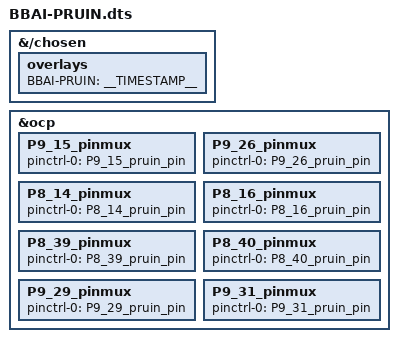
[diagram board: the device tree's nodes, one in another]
/*
 * Copyright (C) 2020 Deepak Khatri <deepaklorkhatri7@gmail.com>
 * See Cape Interface Spec page for more info on Bone Buses
 * https://elinux.org/Beagleboard:BeagleBone_cape_interface_spec
 *
 * Virtual cape for pr2_pru0_gpi* pins
 *
 * This program is free software; you can redistribute it and/or modify
 * it under the terms of the GNU General Public License version 2 as
 * published by the Free Software Foundation.
 */
/dts-v1/;
/plugin/;

/*
* Helper to show loaded overlays under: /proc/device-tree/chosen/overlays/
*/
&{/chosen} {
    overlays {
        BBAI-PRUIN = __TIMESTAMP__;
    };
};

/*
 * Update the default pinmux of the pins.
 * See these files for the phandles (&P9_* & &P8_*)
 * BeagleBoard-DeviceTrees/v4.19.x-ti-overlays/src/arm/am335x-bone-common-univ.dtsi
 * BeagleBoard-DeviceTrees/v4.19.x-ti-overlays/src/arm/am572x-bone-common-univ.dtsi
 */
&ocp {
	P9_15_pinmux { pinctrl-0 = <&P9_15_pruin_pin>; }; /* pr1_pru0_gpi5 */
	P9_26_pinmux { pinctrl-0 = <&P9_26_pruin_pin>; }; /* pr1_pru0_gpi17 */

	P8_14_pinmux { pinctrl-0 = <&P8_14_pruin_pin>; }; /* pr1_pru1_gpi9 */
	P8_16_pinmux { pinctrl-0 = <&P8_16_pruin_pin>; }; /* pr1_pru1_gpi18 */

	P8_39_pinmux { pinctrl-0 = <&P8_39_pruin_pin>; }; /* pr2_pru0_gpi3 */
	P8_40_pinmux { pinctrl-0 = <&P8_40_pruin_pin>; }; /* pr2_pru0_gpi4 */

	P9_29_pinmux { pinctrl-0 = <&P9_29_pruin_pin>; }; /* pr2_pru1_gpi11 */
	P9_31_pinmux { pinctrl-0 = <&P9_31_pruin_pin>; }; /* pr2_pru1_gpi10 */
};
